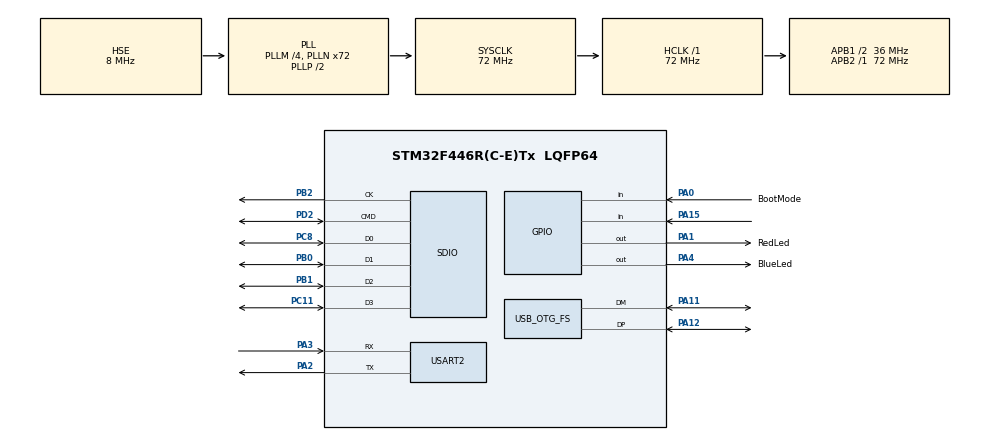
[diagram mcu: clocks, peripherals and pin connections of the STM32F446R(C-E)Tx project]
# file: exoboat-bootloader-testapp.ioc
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Dma.Request0=SDIO_RX
Dma.Request1=SDIO_TX
Dma.SDIO_RX.0.Direction=DMA_PERIPH_TO_MEMORY
Dma.SDIO_RX.0.FIFOMode=DMA_FIFOMODE_ENABLE
Dma.SDIO_RX.0.FIFOThreshold=DMA_FIFO_THRESHOLD_FULL
Dma.SDIO_RX.0.Instance=DMA2_Stream3
Dma.SDIO_RX.0.MemBurst=DMA_MBURST_INC4
Dma.SDIO_RX.0.MemDataAlignment=DMA_MDATAALIGN_WORD
Dma.SDIO_RX.0.MemInc=DMA_MINC_ENABLE
Dma.SDIO_RX.0.Mode=DMA_PFCTRL
Dma.SDIO_RX.0.PeriphBurst=DMA_PBURST_INC4
Dma.SDIO_RX.0.PeriphDataAlignment=DMA_PDATAALIGN_WORD
Dma.SDIO_RX.0.PeriphInc=DMA_PINC_DISABLE
Dma.SDIO_RX.0.Priority=DMA_PRIORITY_LOW
Dma.SDIO_TX.1.Direction=DMA_MEMORY_TO_PERIPH
Dma.SDIO_TX.1.FIFOMode=DMA_FIFOMODE_ENABLE
Dma.SDIO_TX.1.FIFOThreshold=DMA_FIFO_THRESHOLD_FULL
Dma.SDIO_TX.1.Instance=DMA2_Stream6
Dma.SDIO_TX.1.MemBurst=DMA_MBURST_INC4
Dma.SDIO_TX.1.MemDataAlignment=DMA_MDATAALIGN_WORD
Dma.SDIO_TX.1.MemInc=DMA_MINC_ENABLE
Dma.SDIO_TX.1.Mode=DMA_PFCTRL
Dma.SDIO_TX.1.PeriphBurst=DMA_PBURST_INC4
Dma.SDIO_TX.1.PeriphDataAlignment=DMA_PDATAALIGN_WORD
Dma.SDIO_TX.1.PeriphInc=DMA_PINC_DISABLE
Dma.SDIO_TX.1.Priority=DMA_PRIORITY_LOW
FATFS.USE_DMA_CODE_SD=1
Mcu.Family=STM32F4
Mcu.Name=STM32F446R(C-E)Tx
Mcu.Package=LQFP64
NVIC.DMA2_Stream3_IRQn=true\:0\:0\:false\:false\:true\:false\:true\:true
NVIC.DMA2_Stream6_IRQn=true\:0\:0\:false\:false\:true\:false\:true\:true
NVIC.OTG_FS_IRQn=true\:0\:0\:false\:false\:true\:false\:true\:true
NVIC.PriorityGroup=NVIC_PRIORITYGROUP_4
NVIC.SDIO_IRQn=true\:0\:0\:false\:false\:true\:true\:true\:true
PA0-WKUP.GPIO_Label=BootMode
PA0-WKUP.Signal=GPIO_Input
PA1.GPIO_Label=RedLed
PA1.Signal=GPIO_Output
PA11.Mode=Device_Only
PA11.Signal=USB_OTG_FS_DM
PA12.Mode=Device_Only
PA12.Signal=USB_OTG_FS_DP
PA15.Signal=GPIO_Input
PA2.Mode=Asynchronous
PA2.Signal=USART2_TX
PA3.Mode=Asynchronous
PA3.Signal=USART2_RX
PA4.GPIO_Label=BlueLed
PA4.Signal=GPIO_Output
PB0.Mode=SD_4_bits_Wide_bus
PB0.Signal=SDIO_D1
PB1.Mode=SD_4_bits_Wide_bus
PB1.Signal=SDIO_D2
PB2.Mode=SD_4_bits_Wide_bus
PB2.Signal=SDIO_CK
PC11.Mode=SD_4_bits_Wide_bus
PC11.Signal=SDIO_D3
PC8.Mode=SD_4_bits_Wide_bus
PC8.Signal=SDIO_D0
PD2.Mode=SD_4_bits_Wide_bus
PD2.Signal=SDIO_CMD
PH0-OSC_IN.Mode=HSE-External-Oscillator
PH0-OSC_IN.Signal=RCC_OSC_IN
PH1-OSC_OUT.Mode=HSE-External-Oscillator
PH1-OSC_OUT.Signal=RCC_OSC_OUT
ProjectManager.HeapSize=0x200
ProjectManager.StackSize=0x400
ProjectManager.TargetToolchain=STM32CubeIDE
RCC.AHBFreq_Value=72000000
RCC.APB1CLKDivider=RCC_HCLK_DIV2
RCC.APB1Freq_Value=36000000
RCC.APB1TimFreq_Value=72000000
RCC.APB2Freq_Value=72000000
RCC.APB2TimFreq_Value=72000000
RCC.CortexFreq_Value=72000000
RCC.HCLKFreq_Value=72000000
RCC.HSE_VALUE=8000000
RCC.PLLM=4
RCC.PLLN=72
RCC.PLLQ=3
RCC.PLLSourceVirtual=RCC_PLLSOURCE_HSE
RCC.SYSCLKFreq_VALUE=72000000
RCC.SYSCLKSource=RCC_SYSCLKSOURCE_PLLCLK
RCC.USBFreq_Value=48000000
RCC.VCOOutputFreq_Value=144000000
USART2.VirtualMode=VM_ASYNC
USB_DEVICE.CLASS_NAME_FS=MSC
USB_DEVICE.VirtualMode-MSC_FS=Msc
USB_DEVICE.VirtualModeFS=Msc_FS
USB_OTG_FS.VirtualMode=Device_Only
VP_FATFS_VS_SDIO.Mode=SDIO
VP_USB_DEVICE_VS_USB_DEVICE_MSC_FS.Mode=MSC_FS
board=custom

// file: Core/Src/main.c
/* USER CODE BEGIN Header */
/**
  ******************************************************************************
  * @file           : main.c
  * @brief          : Main program body
  ******************************************************************************
  * @attention
  *
  * Copyright (c) 2022 STMicroelectronics.
  * All rights reserved.
  *
  * This software is licensed under terms that can be found in the LICENSE file
  * in the root directory of this software component.
  * If no LICENSE file comes with this software, it is provided AS-IS.
  *
  ******************************************************************************
  */
/* USER CODE END Header */
#include "main.h"
#include "fatfs.h"
#include "usb_device.h"

 SD_HandleTypeDef hsd;
DMA_HandleTypeDef hdma_sdio_rx;
DMA_HandleTypeDef hdma_sdio_tx;

UART_HandleTypeDef huart2;

void SystemClock_Config(void);
static void MX_GPIO_Init(void);
static void MX_USART2_UART_Init(void);
static void MX_DMA_Init(void);
static void MX_SDIO_SD_Init(void);

/* USER CODE BEGIN 0 */

static inline void cpu_delay(unsigned long long ticks)
{
    volatile unsigned long long t = ticks;
    while (t) t=t-1;
}
/* USER CODE END 0 */

void Delay_ms(volatile int time_ms);
int main(void)
{

  /* MCU Configuration--------------------------------------------------------*/

  /* Reset of all peripherals, Initializes the Flash interface and the Systick. */
  HAL_Init();

  /* Configure the system clock */
  SystemClock_Config();

  /* USER CODE BEGIN SysInit */
  SCB->VTOR = 0x08020000;

  /* USER CODE END SysInit */

  /* Initialize all configured peripherals */
  MX_GPIO_Init();
  MX_USART2_UART_Init();
  MX_DMA_Init();
  MX_SDIO_SD_Init();
  //MX_USB_DEVICE_Init();
  //MX_FATFS_Init();

  /* Infinite loop */
  while (1)
  {
	  HAL_GPIO_TogglePin(GPIOA,GPIO_PIN_1|GPIO_PIN_4);
	  //HAL_Delay(500);
	  cpu_delay(2000000);
  }
}

void SystemClock_Config(void)
{
  RCC_OscInitTypeDef RCC_OscInitStruct = {0};
  RCC_ClkInitTypeDef RCC_ClkInitStruct = {0};

  /** Configure the main internal regulator output voltage
  */
  __HAL_RCC_PWR_CLK_ENABLE();
  __HAL_PWR_VOLTAGESCALING_CONFIG(PWR_REGULATOR_VOLTAGE_SCALE3);

  /** Initializes the RCC Oscillators according to the specified parameters
  * in the RCC_OscInitTypeDef structure.
  */
  RCC_OscInitStruct.OscillatorType = RCC_OSCILLATORTYPE_HSE;
  RCC_OscInitStruct.HSEState = RCC_HSE_ON;
  RCC_OscInitStruct.PLL.PLLState = RCC_PLL_ON;
  RCC_OscInitStruct.PLL.PLLSource = RCC_PLLSOURCE_HSE;
  RCC_OscInitStruct.PLL.PLLM = 4;
  RCC_OscInitStruct.PLL.PLLN = 72;
  RCC_OscInitStruct.PLL.PLLP = RCC_PLLP_DIV2;
  RCC_OscInitStruct.PLL.PLLQ = 3;
  RCC_OscInitStruct.PLL.PLLR = 2;
  if (HAL_RCC_OscConfig(&RCC_OscInitStruct) != HAL_OK)
  {
    Error_Handler();
  }

  /** Initializes the CPU, AHB and APB buses clocks
  */
  RCC_ClkInitStruct.ClockType = RCC_CLOCKTYPE_HCLK|RCC_CLOCKTYPE_SYSCLK
                              |RCC_CLOCKTYPE_PCLK1|RCC_CLOCKTYPE_PCLK2;
  RCC_ClkInitStruct.SYSCLKSource = RCC_SYSCLKSOURCE_PLLCLK;
  RCC_ClkInitStruct.AHBCLKDivider = RCC_SYSCLK_DIV1;
  RCC_ClkInitStruct.APB1CLKDivider = RCC_HCLK_DIV2;
  RCC_ClkInitStruct.APB2CLKDivider = RCC_HCLK_DIV1;

  if (HAL_RCC_ClockConfig(&RCC_ClkInitStruct, FLASH_LATENCY_2) != HAL_OK)
  {
    Error_Handler();
  }
}

static void MX_SDIO_SD_Init(void)
{

  hsd.Instance = SDIO;
  hsd.Init.ClockEdge = SDIO_CLOCK_EDGE_RISING;
  hsd.Init.ClockBypass = SDIO_CLOCK_BYPASS_DISABLE;
  hsd.Init.ClockPowerSave = SDIO_CLOCK_POWER_SAVE_DISABLE;
  hsd.Init.BusWide = SDIO_BUS_WIDE_1B;
  hsd.Init.HardwareFlowControl = SDIO_HARDWARE_FLOW_CONTROL_DISABLE;
  hsd.Init.ClockDiv = 0;

}

static void MX_USART2_UART_Init(void)
{

  huart2.Instance = USART2;
  huart2.Init.BaudRate = 115200;
  huart2.Init.WordLength = UART_WORDLENGTH_8B;
  huart2.Init.StopBits = UART_STOPBITS_1;
  huart2.Init.Parity = UART_PARITY_NONE;
  huart2.Init.Mode = UART_MODE_TX_RX;
  huart2.Init.HwFlowCtl = UART_HWCONTROL_NONE;
  huart2.Init.OverSampling = UART_OVERSAMPLING_16;
  if (HAL_UART_Init(&huart2) != HAL_OK)
  {
    Error_Handler();
  }

}

static void MX_DMA_Init(void)
{

  /* DMA controller clock enable */
  __HAL_RCC_DMA2_CLK_ENABLE();

  /* DMA interrupt init */
  /* DMA2_Stream3_IRQn interrupt configuration */
  HAL_NVIC_SetPriority(DMA2_Stream3_IRQn, 0, 0);
  HAL_NVIC_EnableIRQ(DMA2_Stream3_IRQn);
  /* DMA2_Stream6_IRQn interrupt configuration */
  HAL_NVIC_SetPriority(DMA2_Stream6_IRQn, 0, 0);
  HAL_NVIC_EnableIRQ(DMA2_Stream6_IRQn);

}

static void MX_GPIO_Init(void)
{
  GPIO_InitTypeDef GPIO_InitStruct = {0};

  /* GPIO Ports Clock Enable */
  __HAL_RCC_GPIOH_CLK_ENABLE();
  __HAL_RCC_GPIOA_CLK_ENABLE();
  __HAL_RCC_GPIOB_CLK_ENABLE();
  __HAL_RCC_GPIOC_CLK_ENABLE();
  __HAL_RCC_GPIOD_CLK_ENABLE();

  /*Configure GPIO pin Output Level */
  HAL_GPIO_WritePin(GPIOA, RedLed_Pin|BlueLed_Pin, GPIO_PIN_RESET);

  /*Configure GPIO pins : BootMode_Pin PA15 */
  GPIO_InitStruct.Pin = BootMode_Pin|GPIO_PIN_15;
  GPIO_InitStruct.Mode = GPIO_MODE_INPUT;
  GPIO_InitStruct.Pull = GPIO_NOPULL;
  HAL_GPIO_Init(GPIOA, &GPIO_InitStruct);

  /*Configure GPIO pins : RedLed_Pin BlueLed_Pin */
  GPIO_InitStruct.Pin = RedLed_Pin|BlueLed_Pin;
  GPIO_InitStruct.Mode = GPIO_MODE_OUTPUT_PP;
  GPIO_InitStruct.Pull = GPIO_NOPULL;
  GPIO_InitStruct.Speed = GPIO_SPEED_FREQ_LOW;
  HAL_GPIO_Init(GPIOA, &GPIO_InitStruct);

}

void Error_Handler(void)
{
  __disable_irq();
  while (1)
  {
  }
}
